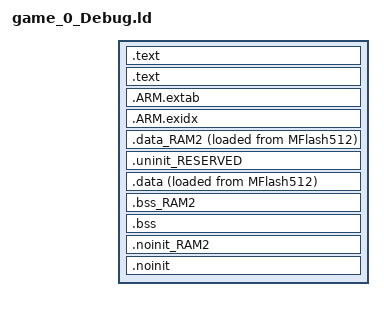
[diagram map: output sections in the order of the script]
/*
 * GENERATED FILE - DO NOT EDIT
 * Copyright (c) 2008-2013 Code Red Technologies Ltd,
 * Copyright 2015, 2018-2019 NXP
 * (c) NXP Semiconductors 2013-2020
 * Generated linker script file for LPC1769
 * Created from linkscript.ldt by FMCreateLinkLibraries
 * Using Freemarker v2.3.23
 * MCUXpresso IDE v11.0.1 [Build 2563] [2019-09-01] on 31-Jan-2020 1:30:28 PM
 */

INCLUDE "game_0_Debug_library.ld"
INCLUDE "game_0_Debug_memory.ld"

ENTRY(ResetISR)

SECTIONS
{
     /* MAIN TEXT SECTION */
    .text : ALIGN(4)
    {
        FILL(0xff)
        __vectors_start__ = ABSOLUTE(.) ;
        KEEP(*(.isr_vector))
        /* Global Section Table */
        . = ALIGN(4) ;
        __section_table_start = .;
        __data_section_table = .;
        LONG(LOADADDR(.data));
        LONG(    ADDR(.data));
        LONG(  SIZEOF(.data));
        LONG(LOADADDR(.data_RAM2));
        LONG(    ADDR(.data_RAM2));
        LONG(  SIZEOF(.data_RAM2));
        __data_section_table_end = .;
        __bss_section_table = .;
        LONG(    ADDR(.bss));
        LONG(  SIZEOF(.bss));
        LONG(    ADDR(.bss_RAM2));
        LONG(  SIZEOF(.bss_RAM2));
        __bss_section_table_end = .;
        __section_table_end = . ;
        /* End of Global Section Table */

        *(.after_vectors*)

        /* Code Read Protection data */
        . = 0x000002FC ;
        PROVIDE(__CRP_WORD_START__ = .) ;
        KEEP(*(.crp))
        PROVIDE(__CRP_WORD_END__ = .) ;
        ASSERT(!(__CRP_WORD_START__ == __CRP_WORD_END__), "Linker CRP Enabled, but no CRP_WORD provided within application");
        /* End of Code Read Protection */
    } > MFlash512

    .text : ALIGN(4)
    {
       *(.text*)
       *(.rodata .rodata.* .constdata .constdata.*)
       . = ALIGN(4);
    } > MFlash512
    /*
     * for exception handling/unwind - some Newlib functions (in common
     * with C++ and STDC++) use this. 
     */
    .ARM.extab : ALIGN(4) 
    {
        *(.ARM.extab* .gnu.linkonce.armextab.*)
    } > MFlash512

    __exidx_start = .;

    .ARM.exidx : ALIGN(4)
    {
        *(.ARM.exidx* .gnu.linkonce.armexidx.*)
    } > MFlash512
    __exidx_end = .;
 
    _etext = .;
        
    /* DATA section for RamAHB32 */

    .data_RAM2 : ALIGN(4)
    {
        FILL(0xff)
        PROVIDE(__start_data_RAM2 = .) ;
        *(.ramfunc.$RAM2)
        *(.ramfunc.$RamAHB32)
        *(.data.$RAM2)
        *(.data.$RamAHB32)
        *(.data.$RAM2.*)
        *(.data.$RamAHB32.*)
        . = ALIGN(4) ;
        PROVIDE(__end_data_RAM2 = .) ;
     } > RamAHB32 AT>MFlash512
    /* MAIN DATA SECTION */
    .uninit_RESERVED (NOLOAD) :
    {
        . = ALIGN(4) ;
        KEEP(*(.bss.$RESERVED*))
       . = ALIGN(4) ;
        _end_uninit_RESERVED = .;
    } > RamLoc32

    /* Main DATA section (RamLoc32) */
    .data : ALIGN(4)
    {
       FILL(0xff)
       _data = . ;
       *(vtable)
       *(.ramfunc*)
       KEEP(*(CodeQuickAccess))
       KEEP(*(DataQuickAccess))
       *(RamFunction)
       *(.data*)
       . = ALIGN(4) ;
       _edata = . ;
    } > RamLoc32 AT>MFlash512

    /* BSS section for RamAHB32 */
    .bss_RAM2 :
    {
       . = ALIGN(4) ;
       PROVIDE(__start_bss_RAM2 = .) ;
       *(.bss.$RAM2)
       *(.bss.$RamAHB32)
       *(.bss.$RAM2.*)
       *(.bss.$RamAHB32.*)
       . = ALIGN (. != 0 ? 4 : 1) ; /* avoid empty segment */
       PROVIDE(__end_bss_RAM2 = .) ;
    } > RamAHB32

    /* MAIN BSS SECTION */
    .bss :
    {
        . = ALIGN(4) ;
        _bss = .;
        *(.bss*)
        *(COMMON)
        . = ALIGN(4) ;
        _ebss = .;
        PROVIDE(end = .);
    } > RamLoc32

    /* NOINIT section for RamAHB32 */
    .noinit_RAM2 (NOLOAD) :
    {
       . = ALIGN(4) ;
       *(.noinit.$RAM2)
       *(.noinit.$RamAHB32)
       *(.noinit.$RAM2.*)
       *(.noinit.$RamAHB32.*)
       . = ALIGN(4) ;
    } > RamAHB32

    /* DEFAULT NOINIT SECTION */
    .noinit (NOLOAD):
    {
         . = ALIGN(4) ;
        _noinit = .;
        *(.noinit*)
         . = ALIGN(4) ;
        _end_noinit = .;
    } > RamLoc32
    PROVIDE(_pvHeapStart = DEFINED(__user_heap_base) ? __user_heap_base : .);
    PROVIDE(_vStackTop = DEFINED(__user_stack_top) ? __user_stack_top : __top_RamLoc32 - 0);

    /* ## Create checksum value (used in startup) ## */
    PROVIDE(__valid_user_code_checksum = 0 - 
                                         (_vStackTop 
                                         + (ResetISR + 1) 
                                         + (NMI_Handler + 1) 
                                         + (HardFault_Handler + 1) 
                                         + (( DEFINED(MemManage_Handler) ? MemManage_Handler : 0 ) + 1)   /* MemManage_Handler may not be defined */
                                         + (( DEFINED(BusFault_Handler) ? BusFault_Handler : 0 ) + 1)     /* BusFault_Handler may not be defined */
                                         + (( DEFINED(UsageFault_Handler) ? UsageFault_Handler : 0 ) + 1) /* UsageFault_Handler may not be defined */
                                         ) );

    /* Provide basic symbols giving location and size of main text
     * block, including initial values of RW data sections. Note that
     * these will need extending to give a complete picture with
     * complex images (e.g multiple Flash banks).
     */
    _image_start = LOADADDR(.text);
    _image_end = LOADADDR(.data) + SIZEOF(.data);
    _image_size = _image_end - _image_start;
}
